# NUC505_v1 register map
File version: 1.0
NUC505_v1 SVD file
Registers are 32-bit, read-write, reset 0x0 unless marked. A register's access mark holds for its fields unless they carry their own. Offsets are from the block's base; lines under a group give offsets from that group; [hi:lo] are bit positions; {n}, {i} and the like mark numbered series; 'fields as' and 'values as' point back to an identical list; <NAME> marks a mode.

## Memory map
0x40000000 GCR blocks up to offset 0x108 — GCR Register Map
0x40000200 CLK blocks up to offset 0x38 — CLKCTRL Register Map
0x40007000 SPIM size 0x3C — SPIM Register Map
0x4000A000 SDH blocks up to offset 0x840 — SDH Register Map
0x4000B000 USBH blocks up to offset 0x208 — USBH Register Map
0x40019000 USBD blocks up to offset 0x708 — USBD Register Map
0x400E1000 SPI1 blocks up to offset 0x34 — SPI Register Map
0x400E2000 ADC size 0xC — ADC Register Map
0x400E3000 GPIO blocks up to offset 0xBC — GPIO Register Map
0x400E4000 I2C0 blocks up to offset 0x44 — I2C Register Map
0x400E5000 I2C1 blocks up to offset 0x44 — I2C Register Map
0x400E6000 PWM blocks up to offset 0x80 — PWM Register Map
0x400E7000 RTC blocks up to offset 0x74 — RTC Register Map
0x400E8000 I2S blocks up to offset 0x4C — I2S Register Map
0x400E9000 SPI0 blocks up to offset 0x34 — SPI Register Map
0x400EA000 TIMER01 blocks up to offset 0x3C — TIMER Register Map
0x400EB000 TIMER23 blocks up to offset 0x3C — TIMER Register Map
0x400EC000 UART0 size 0x3C — UART Register Map
0x400ED000 UART1 size 0x3C — UART Register Map
0x400EE000 UART2 size 0x3C — UART Register Map
0x400EF000 WDT blocks up to offset 0x14 — WDT Register Map
0x400EF100 WWDT blocks up to offset 0x1C — WWDT Register Map
0xE000E000 SCS blocks up to offset 0xF04 — SCS Register Map
{0xE000E400+4n} NVIC_IPR{n} size 0x4 (n=0..7) — SCS Register Map

## NVIC_IPR0 — SCS Register Map
Base 0xE000E400
Same registers: NVIC_IPR1 0xE000E404, NVIC_IPR2 0xE000E408, NVIC_IPR3 0xE000E40C, NVIC_IPR4 0xE000E410, NVIC_IPR5 0xE000E414, NVIC_IPR6 0xE000E418, NVIC_IPR7 0xE000E41C
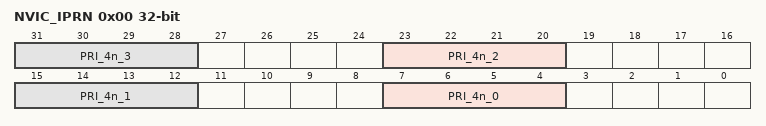
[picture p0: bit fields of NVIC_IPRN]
0x00 NVIC_IPRN — IRQ0 ~ IRQ31 Interrupt Priority Control Register
  [8n+7:8n+4] PRI_4n_{n} (n=0..3) — Priority of IRQ_4n+{n} "0" denotes the highest priority and "15" denotes the lowest priority

## WWDT — WWDT Register Map
Base 0x400EF100
0x00 WWDT_RLDCNT wo — Window Watchdog Timer Reload Counter Register
  [31:0] RLDCNT — WWDT Reload Counter Bits. Writing 0x00005AA5 to this register will reload the Window Watchdog Timer counter value to 0x3F. Software can only write RLDCNT to reload WWDT counter value when current WWDT counter value between 0 and CMPDAT. If software writes RLDCNT when current WWDT counter value is larger than CMPDAT, WWDT reset signal will generate immediately.
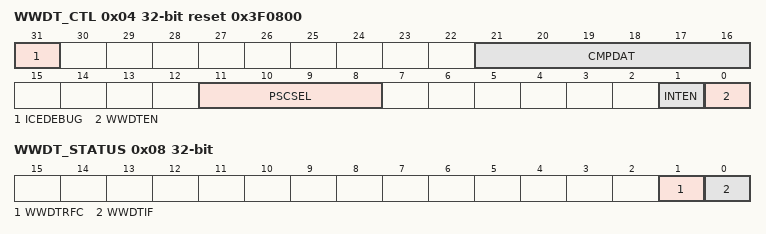
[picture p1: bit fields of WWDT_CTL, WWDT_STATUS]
0x04 WWDT_CTL reset 0x3F0800 — Window Watchdog Timer Control Register
  [31] ICEDEBUG — ICE Debug Mode Acknowledge Disable Control. WWDT down counter will keep going no matter CPU is held by ICE or not.
    0=ICE debug mode acknowledgement effects WWDT counting; 1=ICE debug mode acknowledgement Disabled
  [21:16] CMPDAT — WWDT Window Compare Bits. Set this register to adjust the valid reload window. Software can only write RLDCNT to reload WWDT counter value when current WWDT counter value between 0 and CMPDAT. If Software writes RLDCNT when current WWDT counter value larger than CMPDAT, WWDT reset signal will generate immediately.
  [11:8] PSCSEL — WWDT Counter Prescale Period Selection
    0=Pre-scale is 1; Max time-out period is 1 * 64 * TWWDT; 1=Pre-scale is 2; Max time-out period is 2 * 64 * TWWDT; 2=Pre-scale is 4; Max time-out period is 4 * 64 * TWWDT; 3=Pre-scale is 8; Max time-out period is 8 * 64 * TWWDT; 4=Pre-scale is 16; Max time-out period is 16 * 64 * TWWDT; 5=Pre-scale is 32; Max time-out period is 32 * 64 * TWWDT; 6=Pre-scale is 64; Max time-out period is 64 * 64 * TWWDT; 7=Pre-scale is 128; Max time-out period is 128 * 64 * TWWDT; 8=Pre-scale is 192; Max time-out period is 192 * 64 * TWWDT; 9=Pre-scale is 256; Max time-out period is 256 * 64 * TWWDT; 10=Pre-scale is 384; Max time-out period is 384 * 64 * TWWDT; 11=Pre-scale is 512; Max time-out period is 512 * 64 * TWWDT; 12=Pre-scale is 768; Max time-out period is 768 * 64 * TWWDT; 13=Pre-scale is 1024; Max time-out period is 1024 * 64 * TWWDT; 14=Pre-scale is 1536; Max time-out period is 1536 * 64 * TWWDT; 15=Pre-scale is 2048; Max time-out period is 2048 * 64 * TWWDT
  [1] INTEN — WWDT Interrupt Enable Control. If this bit is enabled, the WWDT counter compare match interrupt signal is generated and inform to CPU.
    0=WWDT counter compare match interrupt Disabled; 1=WWDT counter compare match interrupt Enabled
  [0] WWDTEN — WWDT Enable Control. Set this bit to enable Window Watchdog Timer counter counting.
    0=Window Watchdog Timer counter is stopped; 1=Window Watchdog Timer counter is starting counting
0x08 WWDT_STATUS — Window Watchdog Timer Status Register
  [1] WWDTRFC — WWDT Timer-out Reset Flag Cleared. When the window watch dog reset happened, the register WWDTRF (WWDT_RSTSTS [1]) will be set to 1. Write 1 to this bit and the WWDTRF (WWDT_RSTSTS [1]) will be cleared.
  [0] WWDTIF — WWDT Compare Match Interrupt Flag. This bit indicates the interrupt flag status of WWDT while WWDT counter value matches CMPDAT value. This bit is cleared by writing 1 to WWDT_STATUS[0]
    0=No effect; 1=WWDT counter value matches CMPDAT value
0x0C WWDT_CNT ro reset 0x3F — Window Watchdog Timer Counter Value Register
  [5:0] CNTDAT — WWDT Counter Value. This register reflects the current WWDT counter value and is read only.
0x18 WWDT_RSTSTS ro — Window Watchdog Timer Reset Status Register
  [1] WWDTRF — WWDT Timer-out Reset Flag. This bit indicates the system has been reset by WWDT time-out reset or not. This bit is cleared by writing 1 to WWDTRFC (WWDT_STATUS [1])
    0=WWDT time-out reset did not occur; 1=WWDT time-out reset occurred
